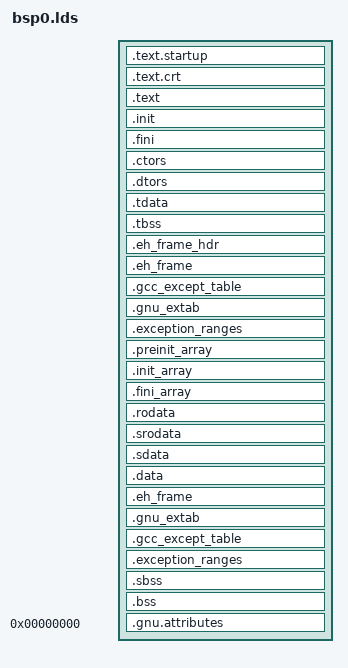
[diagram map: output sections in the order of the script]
/*
*  Syntacore SCR* infra
*
*  @copyright (C) Syntacore 2015-2022. All rights reserved.
*
*  @brief Common part of the bare metal linker script
*/

/*
*  Some external definitions are required:
* - memory layout (MEMORY command)
* - memory regions' aliases (REGION_ALIAS command)
*/

ENTRY(_bsp_start)

SECTIONS {
  /* startup/crt code segment */
  .text.startup ORIGIN(REGION_TEXT) : {
    *(.startup.entry .startup.*)
    . = ALIGN(16);
    *(.init.rodata .init.rodata.*)
    . = ALIGN(16);
    *(.init.data .init.data.*)
    . = ALIGN(16);
    *(.init.text .init.text.*)
  } >REGION_TEXT

  __TEXT_INIT_START__ = LOADADDR(.text.startup);
  __TEXT_INIT_SIZE__ = SIZEOF(.text.startup);

  .text.crt : ALIGN(16) {
    *(.text.crt*)
  } >REGION_TEXT

  /* code segment */
  .text : ALIGN(4) {
    PROVIDE(__TEXT_START__ = .);
    *(.text.unlikely .text.*_unlikely .text.unlikely.*)
    *(.text.exit .text.exit.*)
    *(.text.startup .text.startup.*)
    *(.text.hot .text.hot.*)
    *(.text .stub .text.* .gnu.linkonce.t.*)
    /* .gnu.warning sections are handled specially by elf32.em. */
    *(.gnu.warning)
    PROVIDE(__TEXT_END__ = .);
  } >REGION_TEXT

  /* C++ specific CODE sections */
  .init : {
    KEEP (*(SORT_NONE(.init)))
  } >REGION_TEXT
  .fini : {
    KEEP (*(SORT_NONE(.fini)))
  } >REGION_TEXT
  .ctors : {
    /* gcc uses crtbegin.o to find the start of
       the constructors, so we make sure it is
       first.  Because this is a wildcard, it
       doesn't matter if the user does not
       actually link against crtbegin.o; the
       linker won't look for a file to match a
       wildcard.  The wildcard also means that it
       doesn't matter which directory crtbegin.o
       is in.  */
    KEEP (*crtbegin.o(.ctors))
    KEEP (*crtbegin?.o(.ctors))
    /* We don't want to include the .ctor section from
       the crtend.o file until after the sorted ctors.
       The .ctor section from the crtend file contains the
       end of ctors marker and it must be last */
    KEEP (*(EXCLUDE_FILE (*crtend.o *crtend?.o ) .ctors))
    KEEP (*(SORT(.ctors.*)))
    KEEP (*(.ctors))
  } >REGION_TEXT
  .dtors : {
    KEEP (*crtbegin.o(.dtors))
    KEEP (*crtbegin?.o(.dtors))
    KEEP (*(EXCLUDE_FILE (*crtend.o *crtend?.o ) .dtors))
    KEEP (*(SORT(.dtors.*)))
    KEEP (*(.dtors))
  } >REGION_TEXT

  /* thread-local data segment */
  .tdata : ALIGN(4) {
    PROVIDE(_tls_data = .);
    PROVIDE(_tdata_start = .);
    *(.tdata .tdata.*)
    PROVIDE(_tdata_end = .);
  } >REGION_RODATA

  .tbss : ALIGN(4) {
    PROVIDE(_tbss_start = .);
    *(.tbss .tbss.*)
    . = ALIGN(4);
    PROVIDE(_tbss_end = .);
  } >REGION_RODATA

  __TLS_SIZE__ = (_tbss_end - _tdata_start + 0xf) & ~(0xf);

  /* C++ specific RO sections */
  .eh_frame_hdr : {
    *(.eh_frame_hdr) *(.eh_frame_entry .eh_frame_entry.*)
  } >REGION_RODATA
  /* Exception handling  */
  .eh_frame : ONLY_IF_RO {
    KEEP (*(.eh_frame))
    *(.eh_frame.*)
  } >REGION_RODATA
  .gcc_except_table : ONLY_IF_RO {
    *(.gcc_except_table .gcc_except_table.*)
  } >REGION_RODATA
  .gnu_extab : ONLY_IF_RO {
    *(.gnu_extab*)
  } >REGION_RODATA
  /* These sections are generated by the Sun/Oracle C++ compiler.  */
  .exception_ranges : ONLY_IF_RO {
    *(.exception_ranges .exception_ranges*)
  } >REGION_RODATA
  .preinit_array : {
    PROVIDE_HIDDEN (__preinit_array_start = .);
    KEEP (*(.preinit_array))
    PROVIDE_HIDDEN (__preinit_array_end = .);
  } >REGION_RODATA
  .init_array : {
    PROVIDE_HIDDEN (__init_array_start = .);
    KEEP (*(SORT_BY_INIT_PRIORITY(.init_array.*) SORT_BY_INIT_PRIORITY(.ctors.*)))
    KEEP (*(.init_array EXCLUDE_FILE (*crtbegin.o *crtbegin?.o *crtend.o *crtend?.o ) .ctors))
    PROVIDE_HIDDEN (__init_array_end = .);
  } >REGION_RODATA
  .fini_array : {
    PROVIDE_HIDDEN (__fini_array_start = .);
    KEEP (*(SORT_BY_INIT_PRIORITY(.fini_array.*) SORT_BY_INIT_PRIORITY(.dtors.*)))
    KEEP (*(.fini_array EXCLUDE_FILE (*crtbegin.o *crtbegin?.o *crtend.o *crtend?.o ) .dtors))
    PROVIDE_HIDDEN (__fini_array_end = .);
  } >REGION_RODATA

  /* read-only data segment */
  .rodata : ALIGN(4) {
    *(.rodata) *(.rodata.*) *(.gnu.linkonce.r.*)
  } >REGION_RODATA

  /* small read-only data segment */
  .srodata : {
    *(.srodata.cst16) *(.srodata.cst8) *(.srodata.cst4) *(.srodata.cst2) *(.srodata*)
  } >REGION_RODATA

  /* small data segment */
  .sdata : ALIGN(4) {
    __SDATA_BEGIN__ = .;
    *(.sdata .sdata.* .gnu.linkonce.s.*)
    *(.sdata2 .sdata2.* .gnu.linkonce.s2.*)
  } >REGION_DATA

  /* data segment */
  .data : ALIGN(4) {
    __DATA_BEGIN__ = .;
    *(.data .data.* .gnu.linkonce.d.*)
    SORT(CONSTRUCTORS)
    _edata = .; PROVIDE (edata = .);
  } >REGION_DATA

  /* C++ specific RW sections */
  /* Exception handling */
  .eh_frame : ONLY_IF_RW {
    KEEP (*(.eh_frame))
    *(.eh_frame.*)
  } >REGION_DATA
  .gnu_extab : ONLY_IF_RW {
    *(.gnu_extab)
  } >REGION_DATA
  .gcc_except_table : ONLY_IF_RW {
    *(.gcc_except_table .gcc_except_table.*)
  } >REGION_DATA
  .exception_ranges : ONLY_IF_RW {
    *(.exception_ranges .exception_ranges*)
  } >REGION_DATA

  /* bss segment */
  .sbss : {
    PROVIDE(__bss_start = .);
    *(.sbss .sbss.* .gnu.linkonce.sb.*)
    *(.sbss2 .sbss2.* .gnu.linkonce.sb2.*)
    *(.scommon)
  } >REGION_BSS

  .bss : ALIGN(4) {
    *(.bss .bss.* .gnu.linkonce.b.*)
    *(COMMON)
    . = ALIGN(4);
    __BSS_END__ = .;
    PROVIDE(__bss_end = .);
    PROVIDE(_end = .);
    PROVIDE(__end = .);
  } >REGION_BSS

  /* End of uninitalized data segement */

  __global_pointer$ = MIN(__DATA_BEGIN__ + 0x780,
                          MAX(__SDATA_BEGIN__ + 0x780, __BSS_END__ - 0x780));

  __TLS0_BASE__ = ORIGIN(REGION_STACK) + LENGTH(REGION_STACK) - __TLS_SIZE__;
  PROVIDE(__TLS0_BASE__ = __TLS0_BASE__);

  _heap_start = ALIGN(__bss_end, 16);
  _heap_end_in_stack = ABSOLUTE((ORIGIN(REGION_STACK) == ORIGIN(REGION_BSS)) ? 1 : 0);
  _heap_end_div = 256;
  _mem_origin = _heap_end_in_stack ? ORIGIN(REGION_STACK) : ORIGIN(REGION_BSS);
  _heap_end   = _heap_end_in_stack ? __TLS0_BASE__ - ORIGIN(REGION_STACK) : LENGTH(REGION_BSS);
  PROVIDE(_heap_start = _heap_start);
  PROVIDE(_heap_end = _heap_end);
  _heap_end /= _heap_end_div;
  _heap_end += _mem_origin;
  PROVIDE(_heap_end_div = _heap_end_div);
  PROVIDE(_mem_origin = _mem_origin);
  PROVIDE(_heap_end_in_stack = _heap_end_in_stack);

  /* discard relocation code */
  plf_init_relocate = plf_init_noreloc;

  .gnu.attributes 0 : { KEEP (*(.gnu.attributes)) }
  /DISCARD/ : {
    *(.init.text.plf_init_relocate)
    /* *(.eh_frame .eh_frame.*) */
    *(.note.GNU-stack)
    *(.gnu_debuglink)
    *(.gnu.lto_*)
  }
}
